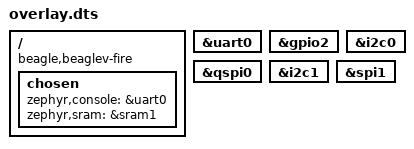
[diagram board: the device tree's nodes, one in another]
/ {
	compatible = "beagle,beaglev-fire", "microchip,mpfs";
	chosen {
		zephyr,console = &uart0;
		zephyr,sram = &sram1;
	};
};
&uart0{
	status = "okay";
};
&gpio2{
	status = "okay";
};
&i2c0{
	status = "okay";
};
&qspi0{
	status = "okay";
};
&i2c1{
	status = "okay";
};
&spi1{
	status = "okay";
};
